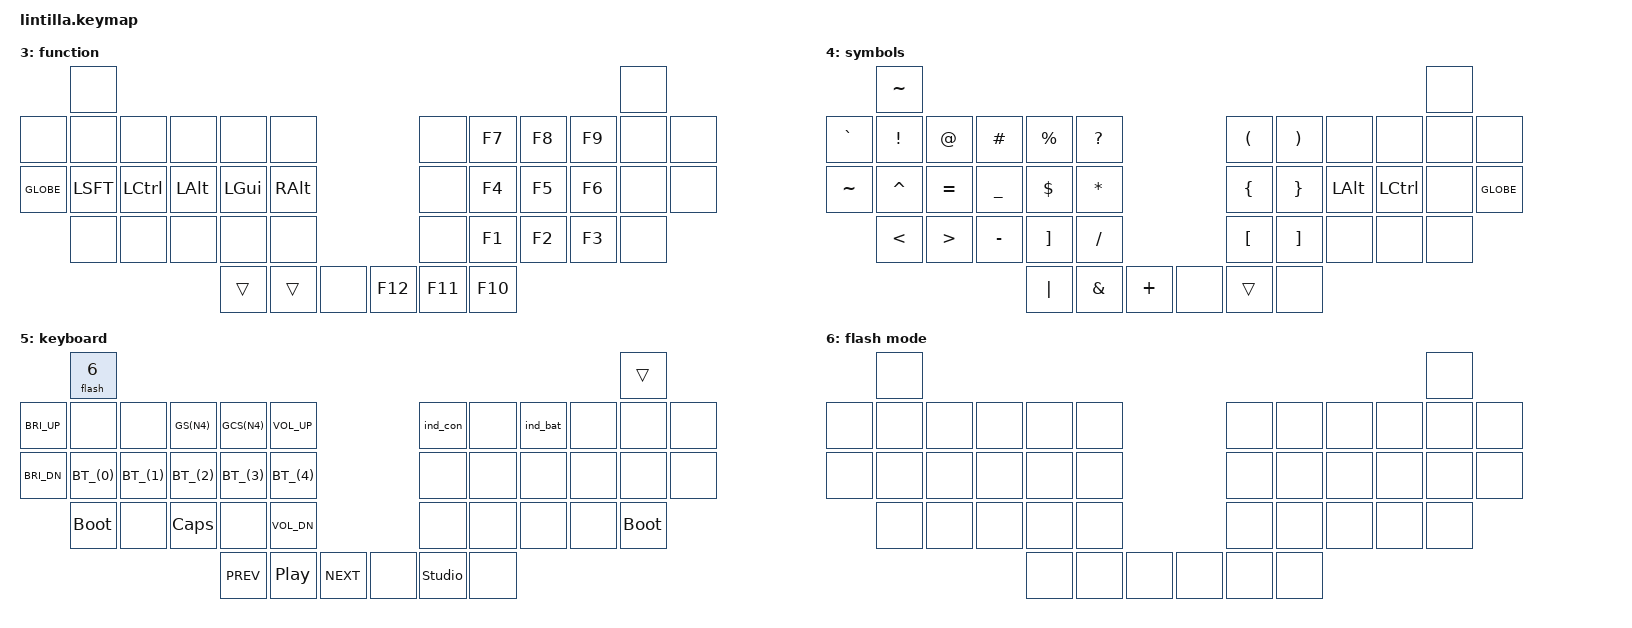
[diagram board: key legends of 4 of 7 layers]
#include <behaviors.dtsi>
#include <dt-bindings/zmk/bt.h>
#include <dt-bindings/zmk/keys.h>
#include <dt-bindings/zmk/outputs.h>
#include <behaviors/rgbled_widget.dtsi>

// Multiple mods
#define GS(key) &kp LG(LS(key))
#define GCS(key) &kp LG(LC(LS(key)))
#define HYPR(key) &kp LG(LA(LC(LS(key))))

// Shortcuts for home row mods
#define Glb &hm GLOBE
#define Sft &hm LSHFT
#define Ctl &hm LCTRL
#define Opt &hm LALT
#define Cmd &hm LGUI
#define Alt &hm RALT

// Magic bluetooth button
#define BT_(btnum) &bt_key btnum btnum

/ {
    behaviors {
        bt_key: magic_bluetooth_key {
            compatible = "zmk,behavior-hold-tap";
            #binding-cells = <2>;
            flavor = "tap-preferred";
            tapping-term-ms = <500>;
            bindings = <&bt_clr>, <&bt_sel>;
        };

        hm: homerow_mod {
            compatible = "zmk,behavior-hold-tap";
            #binding-cells = <2>;
            tapping-term-ms = <300>;
            require-prior-idle-ms = <150>;
            quick-tap-ms = <0>;
            flavor = "tap-preferred";
            bindings = <&kp>, <&kp>;
        };

        lp_mc: launch_pad_mission_control {
            compatible = "zmk,behavior-tap-dance";
            #binding-cells = <0>;
            tapping-term-ms = <200>;
            bindings = <HYPR(N4)>, <&kp LC(UP)>;
        };

        lsscw: layer_sticky_shift_caps_word {
            compatible = "zmk,behavior-hold-tap";
            #binding-cells = <2>;
            flavor = "balanced";
            tapping-term-ms = <200>;
            bindings = <&mo>, <&sscw>;
        };

        mcs: mod_comma_semi {
            compatible = "zmk,behavior-mod-morph";
            #binding-cells = <0>;
            bindings = <&kp COMMA>, <&kp SEMI>;
            mods = <(MOD_LSFT|MOD_RSFT)>;
        };

        mdc: mod_dot_colon {
            compatible = "zmk,behavior-mod-morph";
            #binding-cells = <0>;
            bindings = <&kp DOT>, <&kp COLON>;
            mods = <(MOD_LSFT|MOD_RSFT)>;
        };

        msb: mod_slash_back {
            compatible = "zmk,behavior-mod-morph";
            #binding-cells = <0>;
            bindings = <&kp SLASH>, <&kp BACKSLASH>;
            mods = <(MOD_LSFT|MOD_RSFT)>;
        };

        sscw: sticky_shift_caps_word {
            compatible = "zmk,behavior-mod-morph";
            #binding-cells = <0>;
            bindings = <&sk LSHIFT>, <&caps_word>;
            mods = <(MOD_LSFT|MOD_RSFT)>;
        };
    };

    conditional_layers {
        compatible = "zmk,conditional-layers";
        function_layer {
            if-layers = <1 2>;
            then-layer = <3>;
        };
    };

    macros {
        bt_clr: bluetooth_clear {
            compatible = "zmk,behavior-macro-one-param";
            #binding-cells = <1>;
            bindings = <&macro_param_1to1 &bt_sel MACRO_PLACEHOLDER>, <&bt BT_CLR>;
        };

        bt_sel: bluetooth_select {
            compatible = "zmk,behavior-macro-one-param";
            #binding-cells = <1>;
            bindings = <&out OUT_BLE>, <&macro_param_1to2 &bt BT_SEL MACRO_PLACEHOLDER>;
        };

        flash: dongle_bootloader {
            compatible = "zmk,behavior-macro-one-param";
            #binding-cells = <1>;
            bindings = <&macro_param_1to1 &to MACRO_PLACEHOLDER>, <&bootloader>;
        };
    };

    keymap {
        compatible = "zmk,keymap";

        qwerty {
//                       ┏━━━━━━━━━━━━━━━━━━━━━━━━━┓
            display-name = "Qwerty"                ;
//                       ┗━━━━━━━━━━━━━━━━━━━━━━━━━┛
            bindings = <
//         ┏━━━━━━━┓                                                                                          ┏━━━━━━━┓
//         ┃fn TAB ┃                                                                                          ┃ MUTE  ┃
            &lt 3 TAB                                                                                         &lt 5 K_MUTE
//         ┃       ┃                                                                                          ┃ keybd ┃
// ┏━━━━━━━╋━━━━━━━╋━━━━━━━┳━━━━━━━┳━━━━━━━┳━━━━━━━┓                          ┏━━━━━━━┳━━━━━━━┳━━━━━━━┳━━━━━━━╋━━━━━━━╋━━━━━━━┓
// ┃CT ESC ┃   Q   ┃   W   ┃   E   ┃   R   ┃   T   ┃                          ┃   Y   ┃   U   ┃   I   ┃   O   ┃   P   ┃   ;   ┃
&mt LCTRL ESC &kp Q &kp W &kp E &kp R &kp T                              &kp Y &kp U &kp I &kp O &kp P &kp SEMI
// ┣━━━━━━━╋━━━━━━━╋━━━━━━━╋━━━━━━━╋━━━━━━━╋━━━━━━━┫                          ┣━━━━━━━╋━━━━━━━╋━━━━━━━╋━━━━━━━╋━━━━━━━╋━━━━━━━┫
// ┃nm  ~  ┃   A   ┃   S   ┃   D   ┃   F   ┃   G   ┃                          ┃   H   ┃   J   ┃   K   ┃   L   ┃Sh  '  ┃nv  →  ┃
 &lt 1 TILDE &kp A &kp S &kp D &kp F &kp G                              &kp H &kp J &kp K &kp L Sft SQT &lt 2 RIGHT_ARROW
// ┗━━━━━━━╋━━━━━━━╋━━━━━━━╋━━━━━━━╋━━━━━━━╋━━━━━━━┫                          ┣━━━━━━━╋━━━━━━━╋━━━━━━━╋━━━━━━━╋━━━━━━━╋━━━━━━━┛
//         ┃   Z   ┃   X   ┃   C   ┃   V   ┃   B   ┃                          ┃   N   ┃   M   ┃  , ;  ┃  . :  ┃  / \  ┃
             &kp Z &kp X &kp C &kp V &kp B                              &kp N &kp M &mcs &mdc &msb
//         ┗━━━━━━━┻━━━━━━━┻━━━━━━━┻━━━┳━━━┻━━━┳━━━┻━━━┳━━━━━━━┓  ┏━━━━━━━┳━━━┻━━━┳━━━┻━━━┳━━━┻━━━━━━━┻━━━━━━━┻━━━━━━━┛
//                                     ┃ Cmd   ┃Sh CpW ┃ Alt   ┃  ┃RETURN ┃ BKSPC ┃sy SPC ┃
                             &kp LGUI &lsscw 2 0 &kp LALT &kp RETURN &kp BSPC &lt 4 SPC
//                                     ┗━━━━━━━┫  nav  ┣━━━━━━━┛  ┗━━━━━━━┫  sym  ┣━━━━━━━┛
//                                             ┗━━━━━━━┛                  ┗━━━━━━━┛
            >;
        };

        num {
//                       ┏━━━━━━━━━━━━━━━━━━━━━━━━━┓
            display-name = "numpad"                ;
//                       ┗━━━━━━━━━━━━━━━━━━━━━━━━━┛
            bindings = <
//         ┏━━━━━━━┓                                                                                          ┏━━━━━━━┓
//         ┃       ┃                                                                                          ┃  DEL  ┃
             &none                                                                                             &kp DEL
// ┏━━━━━━━╋━━━━━━━╋━━━━━━━┳━━━━━━━┳━━━━━━━┳━━━━━━━┓                          ┏━━━━━━━┳━━━━━━━┳━━━━━━━┳━━━━━━━╋━━━━━━━╋━━━━━━━┓
// ┃       ┃       ┃       ┃       ┃       ┃       ┃                          ┃   /   ┃   7   ┃   8   ┃   9   ┃   -   ┃ BKSPC ┃
     &none &none &none &none &none &none                            &kp SLASH &kp N7 &kp N8 &kp N9 &kp MINUS &kp BSPC
// ┣━━━━━━━╋━━━━━━━╋━━━━━━━╋━━━━━━━╋━━━━━━━╋━━━━━━━┫                          ┣━━━━━━━╋━━━━━━━╋━━━━━━━╋━━━━━━━╋━━━━━━━╋━━━━━━━┫
// ┃ Globe ┃Sh C-A ┃ Ctrl  ┃Opt C-D┃  Cmd  ┃ R Alt ┃                          ┃   *   ┃   4   ┃   5   ┃   6   ┃   +   ┃RETURN ┃
&kp GLOBE Sft LC(A) &kp LCTL Opt LC(D) &kp LGUI &kp RALT                       &kp STAR &kp N4 &kp N5 &kp N6 &kp PLUS &kp RET
// ┗━━━━━━━╋━━━━━━━╋━━━━━━━╋━━━━━━━╋━━━━━━━╋━━━━━━━┫                          ┣━━━━━━━╋━━━━━━━╋━━━━━━━╋━━━━━━━╋━━━━━━━╋━━━━━━━┛
//         ┃  C-Z  ┃  C-X  ┃  C-C  ┃  C-V  ┃       ┃                          ┃   :   ┃   1   ┃   2   ┃   3   ┃   =   ┃
         &kp LC(Z) &kp LC(X) &kp LC(C) &kp LC(V) &none                        &kp COLON &kp N1 &kp N2 &kp N3 &kp EQUAL
//         ┗━━━━━━━┻━━━━━━━┻━━━━━━━┻━━━┳━━━┻━━━┳━━━┻━━━┳━━━━━━━┓  ┏━━━━━━━┳━━━┻━━━┳━━━┻━━━┳━━━┻━━━━━━━┻━━━━━━━┻━━━━━━━┛
//                                     ┃ ##### ┃ nav fn┃       ┃  ┃   ,   ┃ SPACE ┃   0   ┃
                                         &trans  &mo 2   &none    &kp COMMA &kp SPC &kp N0
//                                     ┗━━━━━━━┫       ┣━━━━━━━┛  ┗━━━━━━━┫       ┣━━━━━━━┛
//                                             ┗━━━━━━━┛                  ┗━━━━━━━┛
            >;
        };

        nav {
//                       ┏━━━━━━━━━━━━━━━━━━━━━━━━━┓
            display-name = "navigation"            ;
//                       ┗━━━━━━━━━━━━━━━━━━━━━━━━━┛
            bindings = <
//         ┏━━━━━━━┓                                                                                          ┏━━━━━━━┓
//         ┃       ┃                                                                                          ┃  DEL  ┃
             &none                                                                                             &kp DEL
// ┏━━━━━━━╋━━━━━━━╋━━━━━━━┳━━━━━━━┳━━━━━━━┳━━━━━━━┓                          ┏━━━━━━━┳━━━━━━━┳━━━━━━━┳━━━━━━━╋━━━━━━━╋━━━━━━━┓
// ┃       ┃       ┃       ┃       ┃       ┃ Pg Up ┃                          ┃ Pg Up ┃       ┃       ┃       ┃       ┃ BKSPC ┃
     &none &none &none &none &none &kp PG_UP                            &kp PG_UP &none &none &none &none &kp BSPC
// ┣━━━━━━━╋━━━━━━━╋━━━━━━━╋━━━━━━━╋━━━━━━━╋━━━━━━━┫                          ┣━━━━━━━╋━━━━━━━╋━━━━━━━╋━━━━━━━╋━━━━━━━╋━━━━━━━┫
// ┃ Globe ┃Sh M-A ┃ Left  ┃  Up   ┃ Right ┃ R Alt ┃                          ┃ Home  ┃ Left  ┃  Up   ┃ Right ┃  End  ┃RETURN ┃
&kp GLOBE Sft LG(A) &kp LEFT &kp UP_ARROW &kp RIGHT &kp RALT                      &kp HOME &kp LEFT &kp UP &kp RIGHT &kp END &kp RET
// ┗━━━━━━━╋━━━━━━━╋━━━━━━━╋━━━━━━━╋━━━━━━━╋━━━━━━━┫                          ┣━━━━━━━╋━━━━━━━╋━━━━━━━╋━━━━━━━╋━━━━━━━╋━━━━━━━┛
//         ┃  M-Z  ┃  M-X  ┃ Down  ┃  M-V  ┃ Pg Dn ┃                          ┃ Pg Dn ┃       ┃ Down  ┃       ┃       ┃
         &kp LG(Z) &kp LG(X) &kp DOWN &kp LG(V) &kp PG_DN                        &kp PG_DN &none &kp DOWN &none &none
//         ┗━━━━━━━┻━━━━━━━┻━━━━━━━┻━━━┳━━━┻━━━┳━━━┻━━━┳━━━━━━━┓  ┏━━━━━━━┳━━━┻━━━┳━━━┻━━━┳━━━┻━━━━━━━┻━━━━━━━┻━━━━━━━┛
//                                     ┃ num fn┃ ##### ┃       ┃  ┃       ┃ SPACE ┃  F10  ┃
                                         &mo 1   &trans  &none      &none  &kp SPC  &kp F10
//                                     ┗━━━━━━━┫       ┣━━━━━━━┛  ┗━━━━━━━┫       ┣━━━━━━━┛
//                                             ┗━━━━━━━┛                  ┗━━━━━━━┛
            >;
        };

        fn {
//                       ┏━━━━━━━━━━━━━━━━━━━━━━━━━┓
            display-name = "function"              ;
//                       ┗━━━━━━━━━━━━━━━━━━━━━━━━━┛
            bindings = <
//         ┏━━━━━━━┓                                                                                          ┏━━━━━━━┓
//         ┃       ┃                                                                                          ┃       ┃
             &none                                                                                              &none
// ┏━━━━━━━╋━━━━━━━╋━━━━━━━┳━━━━━━━┳━━━━━━━┳━━━━━━━┓                          ┏━━━━━━━┳━━━━━━━┳━━━━━━━┳━━━━━━━╋━━━━━━━╋━━━━━━━┓
// ┃       ┃       ┃       ┃       ┃       ┃       ┃                          ┃       ┃  F7   ┃  F8   ┃  F9   ┃       ┃       ┃
     &none   &none   &none   &none   &none   &none                              &none  &kp F7  &kp F8  &kp F9   &none   &none
// ┣━━━━━━━╋━━━━━━━╋━━━━━━━╋━━━━━━━╋━━━━━━━╋━━━━━━━┫                          ┣━━━━━━━╋━━━━━━━╋━━━━━━━╋━━━━━━━╋━━━━━━━╋━━━━━━━┫
// ┃ Globe ┃ Shift ┃ Ctrl  ┃  Opt  ┃  Cmd  ┃ R Alt ┃                          ┃       ┃  F4   ┃  F5   ┃  F6   ┃       ┃       ┃
&kp GLOBE &kp LSFT &kp LCTL &kp LALT &kp LGUI &kp RALT                          &none  &kp F4  &kp F5  &kp F6   &none   &none
// ┗━━━━━━━╋━━━━━━━╋━━━━━━━╋━━━━━━━╋━━━━━━━╋━━━━━━━┫                          ┣━━━━━━━╋━━━━━━━╋━━━━━━━╋━━━━━━━╋━━━━━━━╋━━━━━━━┛
//         ┃       ┃       ┃       ┃       ┃       ┃                          ┃       ┃  F1   ┃  F2   ┃  F3   ┃       ┃
             &none   &none   &none   &none   &none                              &none  &kp F1  &kp F2  &kp F3   &none
//         ┗━━━━━━━┻━━━━━━━┻━━━━━━━┻━━━┳━━━┻━━━┳━━━┻━━━┳━━━━━━━┓  ┏━━━━━━━┳━━━┻━━━┳━━━┻━━━┳━━━┻━━━━━━━┻━━━━━━━┻━━━━━━━┛
//                                     ┃ ##### ┃ ##### ┃       ┃  ┃  F12  ┃  F11  ┃  F10  ┃
                                         &trans  &trans  &none     &kp F12 &kp F11 &kp F10
//                                     ┗━━━━━━━┫       ┣━━━━━━━┛  ┗━━━━━━━┫       ┣━━━━━━━┛
//                                             ┗━━━━━━━┛                  ┗━━━━━━━┛
            >;
        };

        sym {
//                       ┏━━━━━━━━━━━━━━━━━━━━━━━━━┓
            display-name = "symbols"               ;
//                       ┗━━━━━━━━━━━━━━━━━━━━━━━━━┛
            bindings = <
//         ┏━━━━━━━┓                                                                                          ┏━━━━━━━┓
//         ┃   ~   ┃                                                                                          ┃       ┃
        &kp TILDE                                                                                              &none
// ┏━━━━━━━╋━━━━━━━╋━━━━━━━┳━━━━━━━┳━━━━━━━┳━━━━━━━┓                          ┏━━━━━━━┳━━━━━━━┳━━━━━━━┳━━━━━━━╋━━━━━━━╋━━━━━━━┓
// ┃   `   ┃   !   ┃   @   ┃   #   ┃   %   ┃   ?   ┃                          ┃   (   ┃   )   ┃       ┃       ┃       ┃       ┃
&kp GRAVE &kp EXCL &kp AT &kp HASH &kp PRCNT &kp QMARK                        &kp LPAR &kp RPAR &none   &none   &none   &none
// ┣━━━━━━━╋━━━━━━━╋━━━━━━━╋━━━━━━━╋━━━━━━━╋━━━━━━━┫                          ┣━━━━━━━╋━━━━━━━╋━━━━━━━╋━━━━━━━╋━━━━━━━╋━━━━━━━┫
// ┃   ~   ┃   ^   ┃   =   ┃   _   ┃   $   ┃   *   ┃                          ┃   {   ┃   }   ┃  Alt  ┃ Ctrl  ┃       ┃ Globe ┃
&kp TILDE &kp CARET &kp EQUAL &kp UNDER &kp DOLLAR &kp STAR                      &kp LBRC &kp RBRC &kp LALT &kp LCTL &none &kp GLOBE
// ┗━━━━━━━╋━━━━━━━╋━━━━━━━╋━━━━━━━╋━━━━━━━╋━━━━━━━┫                          ┣━━━━━━━╋━━━━━━━╋━━━━━━━╋━━━━━━━╋━━━━━━━╋━━━━━━━┛
//         ┃   <   ┃   >   ┃   -   ┃   ]   ┃   /   ┃                          ┃   [   ┃   ]   ┃       ┃       ┃       ┃
             &kp LT &kp GT &kp MINUS &kp RBKT &kp SLASH                          &kp LBKT &kp RBKT &none &none &none
//         ┗━━━━━━━┻━━━━━━━┻━━━━━━━┻━━━┳━━━┻━━━┳━━━┻━━━┳━━━━━━━┓  ┏━━━━━━━┳━━━┻━━━┳━━━┻━━━┳━━━┻━━━━━━━┻━━━━━━━┻━━━━━━━┛
//                                     ┃   |   ┃   &   ┃   +   ┃  ┃       ┃ ##### ┃       ┃
                                      &kp PIPE &kp AMPS &kp PLUS   &none   &trans  &none
//                                     ┗━━━━━━━┫       ┣━━━━━━━┛  ┗━━━━━━━┫       ┣━━━━━━━┛
//                                             ┗━━━━━━━┛                  ┗━━━━━━━┛
            >;
        };

        keybd {
//                       ┏━━━━━━━━━━━━━━━━━━━━━━━━━┓
            display-name = "keyboard"              ;
//                       ┗━━━━━━━━━━━━━━━━━━━━━━━━━┛
            bindings = <
//         ┏━━━━━━━┓                                                                                          ┏━━━━━━━┓
//         ┃ dongle┃                                                                                          ┃ ##### ┃
           &flash 6                                                                                             &trans
// ┏━━━━━━━╋━━━━━━━╋━━━━━━━┳━━━━━━━┳━━━━━━━┳━━━━━━━┓                          ┏━━━━━━━┳━━━━━━━┳━━━━━━━┳━━━━━━━╋━━━━━━━╋━━━━━━━┓
// ┃ brt + ┃       ┃       ┃scrnsht┃scrn cp┃ vol + ┃                          ┃con led┃       ┃bat led┃       ┃       ┃       ┃
&kp C_BRI_UP &none   &none  GS(N4) GCS(N4) &kp C_VOL_UP                       &ind_con  &none &ind_bat  &none   &none   &none
// ┣━━━━━━━╋━━━━━━━╋━━━━━━━╋━━━━━━━╋━━━━━━━╋━━━━━━━┫                          ┣━━━━━━━╋━━━━━━━╋━━━━━━━╋━━━━━━━╋━━━━━━━╋━━━━━━━┫
// ┃ brt - ┃  BT1  ┃  BT2  ┃  BT3  ┃  BT4  ┃  BT5  ┃                          ┃       ┃       ┃       ┃       ┃       ┃       ┃
&kp C_BRI_DN BT_(0)  BT_(1)  BT_(2)  BT_(3)  BT_(4)                             &none   &none   &none   &none   &none   &none
// ┗━━━━━━━╋━━━━━━━╋━━━━━━━╋━━━━━━━╋━━━━━━━╋━━━━━━━┫                          ┣━━━━━━━╋━━━━━━━╋━━━━━━━╋━━━━━━━╋━━━━━━━╋━━━━━━━┛
//         ┃ flash ┃       ┃caps lk┃       ┃ vol - ┃                          ┃       ┃       ┃       ┃       ┃ flash ┃
        &bootloader &none &kp CAPS &none &kp C_VOL_DN                           &none   &none   &none   &none &bootloader
//         ┗━━━━━━━┻━━━━━━━┻━━━━━━━┻━━━┳━━━┻━━━┳━━━┻━━━┳━━━━━━━┓  ┏━━━━━━━┳━━━┻━━━┳━━━┻━━━┳━━━┻━━━━━━━┻━━━━━━━┻━━━━━━━┛
//                                     ┃ prev  ┃ play  ┃ next  ┃  ┃       ┃studio ┃       ┃
                                   &kp C_PREV &kp C_PP &kp C_NEXT &none &studio_unlock &none
//                                     ┗━━━━━━━┫       ┣━━━━━━━┛  ┗━━━━━━━┫ unlock┣━━━━━━━┛
//                                             ┗━━━━━━━┛                  ┗━━━━━━━┛
            >;
        };

        flash {
//                       ┏━━━━━━━━━━━━━━━━━━━━━━━━━┓
            display-name = "flash mode"            ;
//                       ┗━━━━━━━━━━━━━━━━━━━━━━━━━┛
            bindings = <
//         ┏━━━━━━━┓                                                                                          ┏━━━━━━━┓
//         ┃       ┃                                                                                          ┃       ┃
             &none                                                                                              &none
// ┏━━━━━━━╋━━━━━━━╋━━━━━━━┳━━━━━━━┳━━━━━━━┳━━━━━━━┓                          ┏━━━━━━━┳━━━━━━━┳━━━━━━━┳━━━━━━━╋━━━━━━━╋━━━━━━━┓
// ┃       ┃       ┃       ┃       ┃       ┃       ┃                          ┃       ┃       ┃       ┃       ┃       ┃       ┃
     &none   &none   &none   &none   &none   &none                              &none   &none   &none   &none   &none   &none
// ┣━━━━━━━╋━━━━━━━╋━━━━━━━╋━━━━━━━╋━━━━━━━╋━━━━━━━┫                          ┣━━━━━━━╋━━━━━━━╋━━━━━━━╋━━━━━━━╋━━━━━━━╋━━━━━━━┫
// ┃       ┃       ┃       ┃       ┃       ┃       ┃                          ┃       ┃       ┃       ┃       ┃       ┃       ┃
     &none   &none   &none   &none   &none   &none                              &none   &none   &none   &none   &none   &none
// ┗━━━━━━━╋━━━━━━━╋━━━━━━━╋━━━━━━━╋━━━━━━━╋━━━━━━━┫                          ┣━━━━━━━╋━━━━━━━╋━━━━━━━╋━━━━━━━╋━━━━━━━╋━━━━━━━┛
//         ┃       ┃       ┃       ┃       ┃       ┃                          ┃       ┃       ┃       ┃       ┃       ┃
             &none   &none   &none   &none   &none                              &none   &none   &none   &none   &none
//         ┗━━━━━━━┻━━━━━━━┻━━━━━━━┻━━━┳━━━┻━━━┳━━━┻━━━┳━━━━━━━┓  ┏━━━━━━━┳━━━┻━━━┳━━━┻━━━┳━━━┻━━━━━━━┻━━━━━━━┻━━━━━━━┛
//                                     ┃       ┃       ┃       ┃  ┃       ┃       ┃       ┃
                                         &none   &none   &none      &none   &none   &none
//                                     ┗━━━━━━━┫       ┣━━━━━━━┛  ┗━━━━━━━┫       ┣━━━━━━━┛
//                                             ┗━━━━━━━┛                  ┗━━━━━━━┛
            >;
        };

        // Extra empty layers for ZMK Studio

        layer7 {
            status = "reserved";
        };

        layer8 {
            status = "reserved";
        };

        layer9 {
            status = "reserved";
        };

        layer10 {
            status = "reserved";
        };

        layer11 {
            status = "reserved";
        };

        layer12 {
            status = "reserved";
        };

        layer13 {
            status = "reserved";
        };

        layer14 {
            status = "reserved";
        };

        layer15 {
            status = "reserved";
        };
    };
};

// vim: expandtab softtabstop=4 shiftwidth=4 filetype=dts
